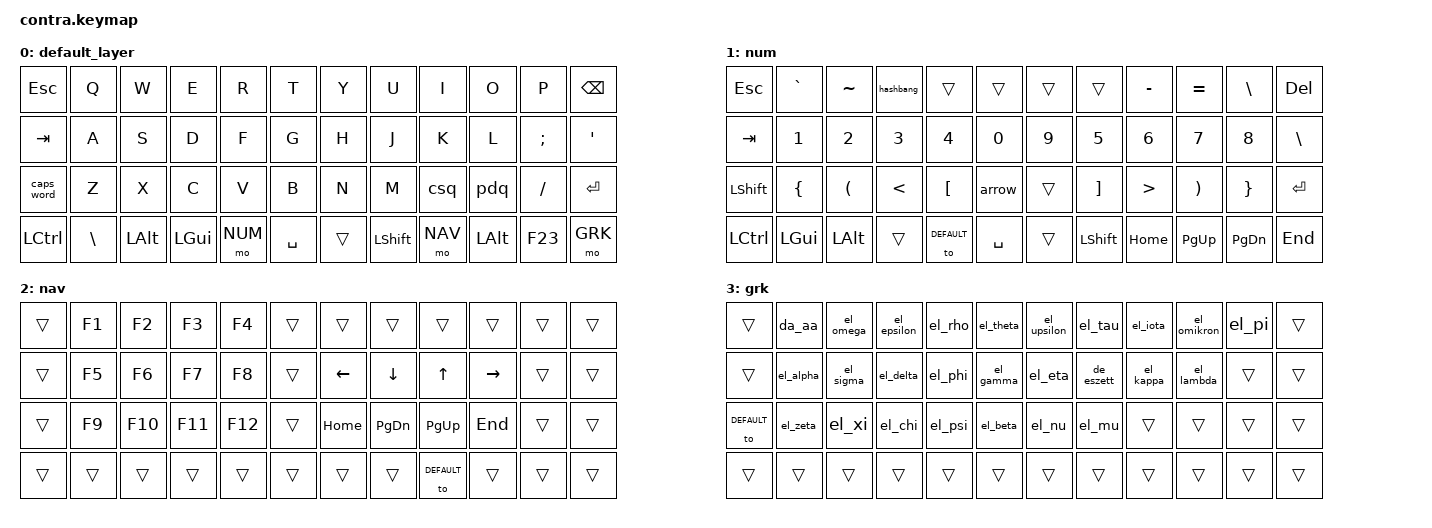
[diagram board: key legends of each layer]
/*
 * Copyright (c) 2021 The ZMK Contributors
 *
 * SPDX-License-Identifier: MIT
 */

#include <behaviors.dtsi>
#include <dt-bindings/zmk/keys.h>
#include <dt-bindings/zmk/bt.h>

#include "zmk-helpers/helper.h"
// Source unicode-chars for desired languages
#define HOST_OS  1
#include "zmk-helpers/unicode-chars/greek.dtsi"
#include "zmk-helpers/unicode-chars/german.dtsi"
#include "zmk-helpers/unicode-chars/danish.dtsi"

#define DEFAULT  0
#define NUM 1
#define NAV  2
#define GRK  3

/ {
    behaviors {
        csq: comma_squote {
             compatible = "zmk,behavior-mod-morph";
             label = "COMMA_SQUOTE";
             #binding-cells = <0>;
             bindings = <&kp COMMA>, <&kp SQT>;
             mods = <(MOD_LSFT)>;
             };
        pdq: period_dquote {
             compatible = "zmk,behavior-mod-morph";
             label = "PERIOD_DQUOTE";
             #binding-cells = <0>;
             bindings = <&kp DOT>, <&kp DQT>;
             mods = <(MOD_LSFT)>;
             };
        arrow: arrow {
            compatible = "zmk,behavior-mod-morph";
            #binding-cells = <0>;
            bindings = <&dash_arrow>, <&eq_arrow>;
            mods = <(MOD_LSFT)>;
        };
    };

    macros {
        dash_arrow: dash_arrow {
            compatible = "zmk,behavior-macro";
            #binding-cells = <0>;
            wait-ms = <40>;
            tap-ms = <40>;
            bindings = <&kp MINUS &kp GT>;
        };
        eq_arrow: eq_arrow {
            compatible = "zmk,behavior-macro";
            #binding-cells = <0>;
            wait-ms = <40>;
            tap-ms = <40>;
            bindings = <&kp EQUAL &kp GT>;
        };
        hashbang: hashbang {
            compatible = "zmk,behavior-macro";
            #binding-cells = <0>;
            wait-ms = <40>;
            tap-ms = <40>;
            bindings = <&kp HASH &kp EXCL>;
        };
    };

    keymap {
        compatible = "zmk,keymap";

        default_layer {
            bindings = <
    &kp ESC   &kp Q     &kp W    &kp E    &kp R    &kp T      &kp Y     &kp U        &kp I     &kp O     &kp P    &kp BSPC
    &kp TAB   &kp A     &kp S    &kp D    &kp F    &kp G      &kp H     &kp J        &kp K     &kp L     &kp SEMI &kp SQT
    &caps_word&kp Z     &kp X    &kp C    &kp V    &kp B      &kp N     &kp M        &csq      &pdq      &kp FSLH &kp ENTER
    &kp LCTRL &kp BSLH  &kp LALT &kp LGUI &mo NUM  &kp SPACE  &trans    &kp LSHFT    &mo NAV   &kp LALT  &kp F23  &mo GRK
            >;
        };

        num {
            bindings = <
    &kp ESC   &kp GRAVE &kp TILDE&hashbang&trans      &trans     &trans    &trans      &kp MINUS &kp EQUAL &kp BSLH &kp DEL
    &kp TAB   &kp N1    &kp N2   &kp N3   &kp N4      &kp N0     &kp N9    &kp N5      &kp N6    &kp N7    &kp N8   &kp BSLH
    &kp LSHFT &kp LBRC  &kp LPAR &kp LT   &kp LBKT    &arrow     &trans    &kp RBKT    &kp GT    &kp RPAR  &kp RBRC &kp ENTER
    &kp LCTRL &kp LGUI  &kp LALT &trans   &to DEFAULT &kp SPACE  &trans    &kp LSHFT   &kp HOME  &kp PG_UP &kp PG_DN&kp END
            >;
        };

        nav {
            bindings = <
    &trans  &kp F1  &kp F2  &kp F3  &kp F4  &trans  &trans    &trans    &trans     &trans     &trans    &trans
    &trans  &kp F5  &kp F6  &kp F7  &kp F8  &trans  &kp LEFT  &kp DOWN  &kp UP     &kp RIGHT  &trans    &trans
    &trans  &kp F9  &kp F10 &kp F11 &kp F12 &trans  &kp HOME  &kp PG_DN &kp PG_UP  &kp END    &trans    &trans
    &trans  &trans  &trans  &trans  &trans  &trans  &trans    &trans    &to DEFAULT&trans     &trans    &trans
            >;
        };

        grk {
            bindings = <
    &trans  &da_aa     &el_omega  &el_epsilon&el_rho    &el_theta  &el_upsilon&el_tau    &el_iota   &el_omikron&el_pi    &trans
    &trans  &el_alpha  &el_sigma  &el_delta  &el_phi    &el_gamma  &el_eta    &de_eszett &el_kappa  &el_lambda &trans    &trans
 &to DEFAULT&el_zeta   &el_xi     &el_chi    &el_psi    &el_beta   &el_nu     &el_mu     &trans     &trans     &trans    &trans
    &trans  &trans     &trans     &trans     &trans     &trans     &trans     &trans     &trans     &trans     &trans    &trans
            >;
        };
    };
};
